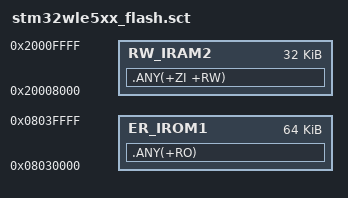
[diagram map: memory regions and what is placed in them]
; *************************************************************
; *** Scatter-Loading Description File generated by uVision ***
; *************************************************************

LR_IROM1 0x08030000 0x00010000  {    ; load region size_region
  ; FLASH for user code
  ER_IROM1 0x08030000 0x00010000  {  ; load address = execution address
	.ANY(+RO)
}
  RW_IRAM2 0x20008000 0x00008000{
	.ANY(+ZI +RW)
  }
}
